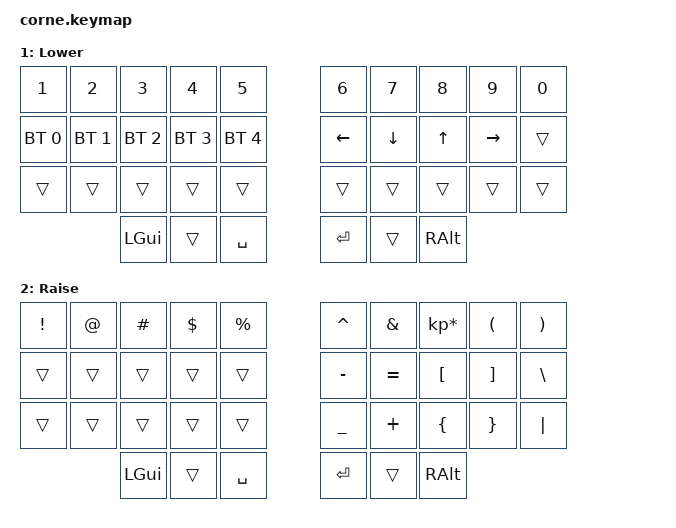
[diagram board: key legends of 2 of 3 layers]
/*
 * Copyright (c) 2020 The ZMK Contributors
 *
 * SPDX-License-Identifier: MIT
 */

#include <behaviors.dtsi>
#include <dt-bindings/zmk/keys.h>
#include <dt-bindings/zmk/bt.h>

/ {
        keymap {
                compatible = "zmk,keymap";

                default_layer {
// -----------------------------------------------------------------------------------------
// |  Q  |  W  |  F  |  P  |  G  |   |  J  |  L   |  U  |  Y  |  ;  |
// |  A  |  R  |  S  |  T  |  D  |   |  H  |  N   |  E  |  I  |  O  |
// |  Z  |  X  |  C  |  V  |  B  |   |  K  |  M   |  ,  |  .  |  /  |
//                    | GUI | LWR | SPC |   | ENT | RSE  | ALT |
                        label = "Base";
                        bindings = <
   &kp Q &kp W &kp F &kp P &kp G   &kp J &kp L  &kp U     &kp Y   &kp ;    
   &kp A &kp R &kp S &kp T &kp D   &kp H &kp N  &kp E     &kp I   &kp SEMI 
   &kp Z &kp X &kp C &kp V &kp B   &kp K &kp M  &kp COMMA &kp DOT &kp FSLH 
                  &kp LGUI &kp SPACE &kp ESC   &kp RET &mo 2 &kp RALT
                        >;
                };
                lower_layer {
// -----------------------------------------------------------------------------------------
// |  1  |  2  |  3  |  4  |  5  |   |  6  |  7  |  8  |  9  |  0  |
// | BT1 | BT2 | BT3 | BT4 | BT5 |   | LFT | DWN |  UP | RGT |     |
// |     |     |     |     |     |   |     |     |     |     |     |
//                    | GUI |     | SPC |   | ENT |     | ALT |
                        label = "Lower";
                        bindings = <
   &kp N1       &kp N2       &kp N3       &kp N4       &kp N5         &kp N6   &kp N7   &kp N8 &kp N9    &kp N0 
   &bt BT_SEL 0 &bt BT_SEL 1 &bt BT_SEL 2 &bt BT_SEL 3 &bt BT_SEL 4   &kp LEFT &kp DOWN &kp UP &kp RIGHT &trans 
   &trans       &trans       &trans       &trans       &trans         &trans   &trans   &trans &trans    &trans 
                          	        &kp LGUI     &trans       &kp SPACE      &kp RET  &trans   &kp RALT
                        >;
                };

                raise_layer {
// -----------------------------------------------------------------------------------------
// |  !  |  @  |  #  |  $  |  %  |   |  ^  |  &  |  *  |  (  |  )  |
// |     |     |     |     |     |   |  -  |  =  |  [  |  ]  |  \  |
// |     |     |     |     |     |   |  _  |  +  |  {  |  }  | "|" |
//                    | GUI |     | SPC |   | ENT |     | ALT |
                        label = "Raise";
                        bindings = <
   &kp EXCL &kp AT &kp HASH &kp DLLR &kp PRCNT   &kp CARET &kp AMPS  &kp KP_MULTIPLY &kp LPAR &kp RPAR 
   &trans   &trans &trans   &trans   &trans      &kp MINUS &kp EQUAL &kp LBKT        &kp RBKT &kp BSLH 
   &trans   &trans &trans   &trans   &trans      &kp UNDER &kp PLUS  &kp LBRC        &kp RBRC &kp PIPE 
                    	     &kp LGUI &trans   &kp SPACE   &kp RET   &trans    &kp RALT
                        >;
                };
        };
};
